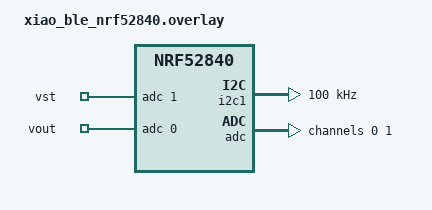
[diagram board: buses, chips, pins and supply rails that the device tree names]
#include <zephyr/dt-bindings/adc/adc.h>
#include <zephyr/dt-bindings/adc/nrf-saadc.h>
#include <zephyr/dt-bindings/i2c/i2c.h>

/ {
	zephyr,user {
		io-channels = <&adc 1>, <&adc 0>;
		io-channel-names = "vst", "vout";
	};
};

/* I2C on XIAO D4 (SDA) / D5 (SCL). The SHT40 (0x44) and ADS1115 (0x48) are powered
 * from LTC3108 VOUT and are read directly by main.c, so they have no driver nodes
 * here. (Zephyr's drivers probe once at boot and stay failed if VOUT is not up yet.) */
&i2c1 {
	status = "okay";
	clock-frequency = <I2C_BITRATE_STANDARD>;
};

&adc {
	status = "okay";
	#address-cells = <1>;
	#size-cells = <0>;

	channel@0 {
		reg = <0>;
		zephyr,gain = "ADC_GAIN_1_6";
		zephyr,reference = "ADC_REF_INTERNAL";
		/* Longer acquisition for the high-resistance voltage divider. */
		zephyr,acquisition-time = <ADC_ACQ_TIME(ADC_ACQ_TIME_MICROSECONDS, 40)>;
		/* XIAO D0/A0 = P0.02 = SAADC AIN0, not GPIO P0.00. */
		zephyr,input-positive = <NRF_SAADC_AIN0>;
		zephyr,resolution = <12>;
	};

	channel@1 {
		reg = <1>;
		zephyr,gain = "ADC_GAIN_1_6";
		zephyr,reference = "ADC_REF_INTERNAL";
		zephyr,acquisition-time = <ADC_ACQ_TIME(ADC_ACQ_TIME_MICROSECONDS, 40)>;
		/* XIAO D1/A1 = P0.03 = SAADC AIN1. */
		zephyr,input-positive = <NRF_SAADC_AIN1>;
		zephyr,resolution = <12>;
	};
};
